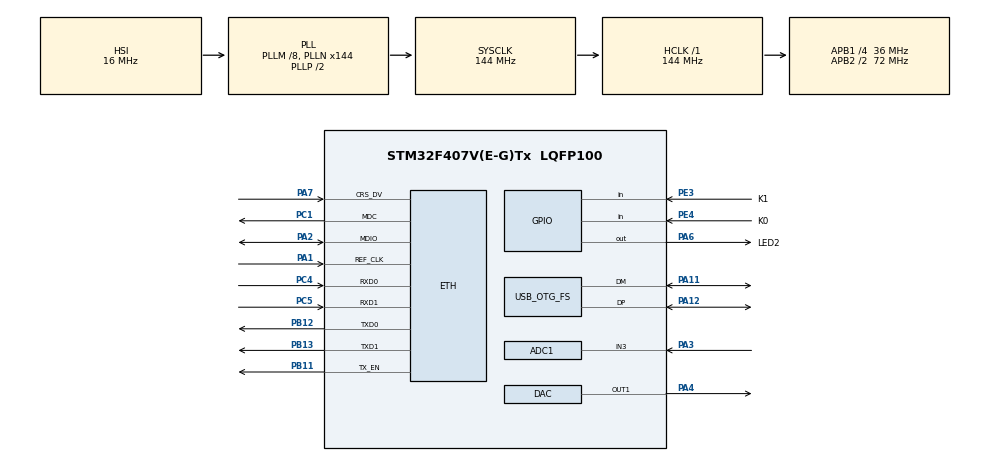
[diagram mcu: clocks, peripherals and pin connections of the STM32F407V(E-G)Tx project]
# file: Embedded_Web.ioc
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ADC1.Channel-8\#ChannelRegularConversion=ADC_CHANNEL_3
ADC1.ClockPrescaler=ADC_CLOCK_SYNC_PCLK_DIV6
ADC1.ContinuousConvMode=ENABLE
ADC1.DMAContinuousRequests=DISABLE
ADC1.DataAlign=ADC_DATAALIGN_RIGHT
ADC1.DiscontinuousConvMode=DISABLE
ADC1.EOCSelection=ADC_EOC_SEQ_CONV
ADC1.EnableAnalogWatchDog=false
ADC1.ExternalTrigConv=ADC_SOFTWARE_START
ADC1.ExternalTrigConvEdge=ADC_EXTERNALTRIGCONVEDGE_NONE
ADC1.InjNumberOfConversion=0
ADC1.NbrOfConversion=1
ADC1.NbrOfConversionFlag=1
ADC1.Rank-8\#ChannelRegularConversion=1
ADC1.Resolution=ADC_RESOLUTION_12B
ADC1.SamplingTime-8\#ChannelRegularConversion=ADC_SAMPLETIME_56CYCLES
ADC1.ScanConvMode=DISABLE
ADC1.master=1
ETH.MediaInterface=ETH_MEDIA_INTERFACE_RMII
FREERTOS.INCLUDE_vTaskDelayUntil=1
FREERTOS.Tasks01=defaultTask,0,128,StartDefaultTask,Default,NULL,Dynamic,NULL,NULL;Task2,-2,128,vTask2,Default,NULL,Dynamic,NULL,NULL;Task3,-2,128,vTask3,Default,NULL,Dynamic,NULL,NULL
FREERTOS.configMINIMAL_STACK_SIZE=128
FREERTOS.configUSE_COUNTING_SEMAPHORES=1
FREERTOS.configUSE_RECURSIVE_MUTEXES=1
LWIP.HTTPD_USE_CUSTOM_FSDATA=1
LWIP.LWIP_HTTPD=1
LWIP.LWIP_HTTPD_CGI=1
LWIP.LWIP_HTTPD_CGI_SSI=0
LWIP.LWIP_HTTPD_SSI=1
LWIP.LWIP_HTTPD_SSI_INCLUDE_TAG=0
LWIP.LWIP_HTTPD_SSI_RAW=0
LWIP.Version=v2.0.3_Cube
Mcu.Family=STM32F4
Mcu.Name=STM32F407V(E-G)Tx
Mcu.Package=LQFP100
NVIC.ETH_IRQn=true\:5\:0\:false\:false\:true\:true\:false
NVIC.OTG_FS_IRQn=true\:5\:0\:false\:false\:true\:true\:false
NVIC.PriorityGroup=NVIC_PRIORITYGROUP_4
NVIC.TIM1_UP_TIM10_IRQn=true\:0\:0\:false\:false\:true\:false\:false
NVIC.TIM6_DAC_IRQn=true\:5\:0\:false\:false\:true\:true\:true
NVIC.TimeBase=TIM1_UP_TIM10_IRQn
NVIC.TimeBaseIP=TIM1
PA0-WKUP.Signal=SYS_WKUP
PA1.Mode=RMII
PA1.Signal=ETH_REF_CLK
PA11.Mode=Device_Only
PA11.Signal=USB_OTG_FS_DM
PA12.Mode=Device_Only
PA12.Signal=USB_OTG_FS_DP
PA13.Mode=Trace_Asynchronous_SW
PA13.Signal=SYS_JTMS-SWDIO
PA14.Mode=Trace_Asynchronous_SW
PA14.Signal=SYS_JTCK-SWCLK
PA2.Mode=RMII
PA2.Signal=ETH_MDIO
PA3.Signal=ADCx_IN3
PA4.Signal=COMP_DAC1_group
PA6.GPIO_Label=LED2
PA6.PinState=GPIO_PIN_SET
PA6.Signal=GPIO_Output
PA7.Mode=RMII
PA7.Signal=ETH_CRS_DV
PB11.Mode=RMII
PB11.Signal=ETH_TX_EN
PB12.Mode=RMII
PB12.Signal=ETH_TXD0
PB13.Mode=RMII
PB13.Signal=ETH_TXD1
PB3.Mode=Trace_Asynchronous_SW
PB3.Signal=SYS_JTDO-SWO
PC1.Mode=RMII
PC1.Signal=ETH_MDC
PC14-OSC32_IN.Mode=LSE-External-Oscillator
PC14-OSC32_IN.Signal=RCC_OSC32_IN
PC15-OSC32_OUT.Mode=LSE-External-Oscillator
PC15-OSC32_OUT.Signal=RCC_OSC32_OUT
PC4.Mode=RMII
PC4.Signal=ETH_RXD0
PC5.Mode=RMII
PC5.Signal=ETH_RXD1
PE3.GPIO_Label=K1
PE3.Signal=GPIO_Input
PE4.GPIO_Label=K0
PE4.GPIO_PuPd=GPIO_PULLUP
PE4.Signal=GPIO_Input
PH0-OSC_IN.Mode=HSE-External-Oscillator
PH0-OSC_IN.Signal=RCC_OSC_IN
PH1-OSC_OUT.Mode=HSE-External-Oscillator
PH1-OSC_OUT.Signal=RCC_OSC_OUT
ProjectManager.HeapSize=0x4000
ProjectManager.StackSize=0x2000
ProjectManager.TargetToolchain=SW4STM32
RCC.48MHZClocksFreq_Value=48000000
RCC.AHBFreq_Value=144000000
RCC.APB1CLKDivider=RCC_HCLK_DIV4
RCC.APB1Freq_Value=36000000
RCC.APB1TimFreq_Value=72000000
RCC.APB2CLKDivider=RCC_HCLK_DIV2
RCC.APB2Freq_Value=72000000
RCC.APB2TimFreq_Value=144000000
RCC.CortexFreq_Value=144000000
RCC.HCLKFreq_Value=144000000
RCC.HSE_Timout=100
RCC.HSE_VALUE=8000000
RCC.HSICalibrationValue=17
RCC.HSI_VALUE=16000000
RCC.PLLM=8
RCC.PLLN=144
RCC.PLLQ=6
RCC.PLLSource=RCC_PLLSOURCE_HSI
RCC.PLLSourceVirtualString=RCC_PLLSOURCE_HSI
RCC.RCC_RTC_Clock_Source=RCC_RTCCLKSOURCE_LSE
RCC.RCC_RTC_Clock_SourceVirtual=RCC_RTCCLKSOURCE_LSE
RCC.SYSCLKFreq_VALUE=144000000
RCC.SYSCLKSource=RCC_SYSCLKSOURCE_PLLCLK
RCC.VCOOutputFreq_Value=288000000
RTC.Date=15
RTC.Hours=9
RTC.Month=RTC_MONTH_JUNE
RTC.Year=18
SH.ADCx_IN3.0=ADC1_IN3,IN3
SH.COMP_DAC1_group.0=DAC_OUT1,DAC_OUT1
USB_DEVICE.CLASS_NAME_FS=CDC
USB_DEVICE.VirtualMode-CDC_FS=Cdc
USB_DEVICE.VirtualModeFS=Cdc_FS
USB_OTG_FS.VirtualMode=Device_Only
VP_FREERTOS_VS_ENABLE.Mode=Enabled
VP_LWIP_VS_Enabled.Mode=Enabled
VP_RTC_VS_RTC_Activate.Mode=RTC_Enabled
VP_RTC_VS_RTC_Calendar.Mode=RTC_Calendar
VP_SYS_VS_tim1.Mode=TIM1
VP_USB_DEVICE_VS_USB_DEVICE_CDC_FS.Mode=CDC_FS
board=Embedded_Web

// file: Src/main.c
/**
  ******************************************************************************
  * @file           : main.c
  * @brief          : Main program body
  ******************************************************************************
  * This notice applies to any and all portions of this file
  * that are not between comment pairs USER CODE BEGIN and
  * USER CODE END. Other portions of this file, whether
  * inserted by the user or by software development tools
  * are owned by their respective copyright owners.
  *
  * Copyright (c) 2018 STMicroelectronics International N.V.
  * All rights reserved.
  *
  * Redistribution and use in source and binary forms, with or without
  * modification, are permitted, provided that the following conditions are met:
  *
  * 1. Redistribution of source code must retain the above copyright notice,
  *    this list of conditions and the following disclaimer.
  * 2. Redistributions in binary form must reproduce the above copyright notice,
  *    this list of conditions and the following disclaimer in the documentation
  *    and/or other materials provided with the distribution.
  * 3. Neither the name of STMicroelectronics nor the names of other
  *    contributors to this software may be used to endorse or promote products
  *    derived from this software without specific written permission.
  * 4. This software, including modifications and/or derivative works of this
  *    software, must execute solely and exclusively on microcontroller or
  *    microprocessor devices manufactured by or for STMicroelectronics.
  * 5. Redistribution and use of this software other than as permitted under
  *    this license is void and will automatically terminate your rights under
  *    this license.
  *
  * THIS SOFTWARE IS PROVIDED BY STMICROELECTRONICS AND CONTRIBUTORS "AS IS"
  * AND ANY EXPRESS, IMPLIED OR STATUTORY WARRANTIES, INCLUDING, BUT NOT
  * LIMITED TO, THE IMPLIED WARRANTIES OF MERCHANTABILITY, FITNESS FOR A
  * PARTICULAR PURPOSE AND NON-INFRINGEMENT OF THIRD PARTY INTELLECTUAL PROPERTY
  * RIGHTS ARE DISCLAIMED TO THE FULLEST EXTENT PERMITTED BY LAW. IN NO EVENT
  * SHALL STMICROELECTRONICS OR CONTRIBUTORS BE LIABLE FOR ANY DIRECT, INDIRECT,
  * INCIDENTAL, SPECIAL, EXEMPLARY, OR CONSEQUENTIAL DAMAGES (INCLUDING, BUT NOT
  * LIMITED TO, PROCUREMENT OF SUBSTITUTE GOODS OR SERVICES; LOSS OF USE, DATA,
  * OR PROFITS; OR BUSINESS INTERRUPTION) HOWEVER CAUSED AND ON ANY THEORY OF
  * LIABILITY, WHETHER IN CONTRACT, STRICT LIABILITY, OR TORT (INCLUDING
  * NEGLIGENCE OR OTHERWISE) ARISING IN ANY WAY OUT OF THE USE OF THIS SOFTWARE,
  * EVEN IF ADVISED OF THE POSSIBILITY OF SUCH DAMAGE.
  *
  ******************************************************************************
  */
#include "main.h"
#include "stm32f4xx_hal.h"
#include "cmsis_os.h"
#include "lwip.h"
#include "usb_device.h"

ADC_HandleTypeDef hadc1;

DAC_HandleTypeDef hdac;

RTC_HandleTypeDef hrtc;

osThreadId defaultTaskHandle;
osThreadId Task2Handle;
osThreadId Task3Handle;

/* USER CODE BEGIN PV */
/* Private variables ---------------------------------------------------------*/
// LED status variables
char LEDs[4];

/* USER CODE END PV */

void SystemClock_Config(void);
static void MX_GPIO_Init(void);
static void MX_DAC_Init(void);
static void MX_ADC1_Init(void);
static void MX_RTC_Init(void);
void StartDefaultTask(void const * argument);
void vTask2(void const * argument);
void vTask3(void const * argument);

/* USER CODE BEGIN PFP */
/* Private function prototypes -----------------------------------------------*/

/* USER CODE END PFP */

int main(void)
{

  /* MCU Configuration----------------------------------------------------------*/

  /* Reset of all peripherals, Initializes the Flash interface and the Systick. */
  HAL_Init();

  /* Configure the system clock */
  SystemClock_Config();

  /* Initialize all configured peripherals */
  MX_GPIO_Init();
  MX_DAC_Init();
  MX_ADC1_Init();
  MX_RTC_Init();

  /* Create the thread(s) */
  /* definition and creation of defaultTask */
  osThreadDef(defaultTask, StartDefaultTask, osPriorityNormal, 0, 128);
  defaultTaskHandle = osThreadCreate(osThread(defaultTask), NULL);

  /* definition and creation of Task2 */
  osThreadDef(Task2, vTask2, osPriorityLow, 0, 128);
  Task2Handle = osThreadCreate(osThread(Task2), NULL);

  /* definition and creation of Task3 */
  osThreadDef(Task3, vTask3, osPriorityLow, 0, 128);
  Task3Handle = osThreadCreate(osThread(Task3), NULL);

  /* Start scheduler */
  osKernelStart();

  /* We should never get here as control is now taken by the scheduler */

  /* Infinite loop */
  while (1)
  {

  }

}

void SystemClock_Config(void)
{

  RCC_OscInitTypeDef RCC_OscInitStruct;
  RCC_ClkInitTypeDef RCC_ClkInitStruct;
  RCC_PeriphCLKInitTypeDef PeriphClkInitStruct;

    /**Configure the main internal regulator output voltage
    */
  __HAL_RCC_PWR_CLK_ENABLE();

  __HAL_PWR_VOLTAGESCALING_CONFIG(PWR_REGULATOR_VOLTAGE_SCALE1);

    /**Initializes the CPU, AHB and APB busses clocks
    */
  RCC_OscInitStruct.OscillatorType = RCC_OSCILLATORTYPE_HSI|RCC_OSCILLATORTYPE_LSE;
  RCC_OscInitStruct.LSEState = RCC_LSE_ON;
  RCC_OscInitStruct.HSIState = RCC_HSI_ON;
  RCC_OscInitStruct.HSICalibrationValue = 17;
  RCC_OscInitStruct.PLL.PLLState = RCC_PLL_ON;
  RCC_OscInitStruct.PLL.PLLSource = RCC_PLLSOURCE_HSI;
  RCC_OscInitStruct.PLL.PLLM = 8;
  RCC_OscInitStruct.PLL.PLLN = 144;
  RCC_OscInitStruct.PLL.PLLP = RCC_PLLP_DIV2;
  RCC_OscInitStruct.PLL.PLLQ = 6;
  if (HAL_RCC_OscConfig(&RCC_OscInitStruct) != HAL_OK)
  {
    _Error_Handler(__FILE__, __LINE__);
  }

    /**Initializes the CPU, AHB and APB busses clocks
    */
  RCC_ClkInitStruct.ClockType = RCC_CLOCKTYPE_HCLK|RCC_CLOCKTYPE_SYSCLK
                              |RCC_CLOCKTYPE_PCLK1|RCC_CLOCKTYPE_PCLK2;
  RCC_ClkInitStruct.SYSCLKSource = RCC_SYSCLKSOURCE_PLLCLK;
  RCC_ClkInitStruct.AHBCLKDivider = RCC_SYSCLK_DIV1;
  RCC_ClkInitStruct.APB1CLKDivider = RCC_HCLK_DIV4;
  RCC_ClkInitStruct.APB2CLKDivider = RCC_HCLK_DIV2;

  if (HAL_RCC_ClockConfig(&RCC_ClkInitStruct, FLASH_LATENCY_4) != HAL_OK)
  {
    _Error_Handler(__FILE__, __LINE__);
  }

  PeriphClkInitStruct.PeriphClockSelection = RCC_PERIPHCLK_RTC;
  PeriphClkInitStruct.RTCClockSelection = RCC_RTCCLKSOURCE_LSE;
  if (HAL_RCCEx_PeriphCLKConfig(&PeriphClkInitStruct) != HAL_OK)
  {
    _Error_Handler(__FILE__, __LINE__);
  }

    /**Configure the Systick interrupt time
    */
  HAL_SYSTICK_Config(HAL_RCC_GetHCLKFreq()/1000);

    /**Configure the Systick
    */
  HAL_SYSTICK_CLKSourceConfig(SYSTICK_CLKSOURCE_HCLK);

  /* SysTick_IRQn interrupt configuration */
  HAL_NVIC_SetPriority(SysTick_IRQn, 15, 0);
}

/* ADC1 init function */
static void MX_ADC1_Init(void)
{

  ADC_ChannelConfTypeDef sConfig;

    /**Configure the global features of the ADC (Clock, Resolution, Data Alignment and number of conversion)
    */
  hadc1.Instance = ADC1;
  hadc1.Init.ClockPrescaler = ADC_CLOCK_SYNC_PCLK_DIV6;
  hadc1.Init.Resolution = ADC_RESOLUTION_12B;
  hadc1.Init.ScanConvMode = DISABLE;
  hadc1.Init.ContinuousConvMode = ENABLE;
  hadc1.Init.DiscontinuousConvMode = DISABLE;
  hadc1.Init.ExternalTrigConvEdge = ADC_EXTERNALTRIGCONVEDGE_NONE;
  hadc1.Init.ExternalTrigConv = ADC_SOFTWARE_START;
  hadc1.Init.DataAlign = ADC_DATAALIGN_RIGHT;
  hadc1.Init.NbrOfConversion = 1;
  hadc1.Init.DMAContinuousRequests = DISABLE;
  hadc1.Init.EOCSelection = ADC_EOC_SEQ_CONV;
  if (HAL_ADC_Init(&hadc1) != HAL_OK)
  {
    _Error_Handler(__FILE__, __LINE__);
  }

    /**Configure for the selected ADC regular channel its corresponding rank in the sequencer and its sample time.
    */
  sConfig.Channel = ADC_CHANNEL_3;
  sConfig.Rank = 1;
  sConfig.SamplingTime = ADC_SAMPLETIME_56CYCLES;
  if (HAL_ADC_ConfigChannel(&hadc1, &sConfig) != HAL_OK)
  {
    _Error_Handler(__FILE__, __LINE__);
  }

}

/* DAC init function */
static void MX_DAC_Init(void)
{

  DAC_ChannelConfTypeDef sConfig;

    /**DAC Initialization
    */
  hdac.Instance = DAC;
  if (HAL_DAC_Init(&hdac) != HAL_OK)
  {
    _Error_Handler(__FILE__, __LINE__);
  }

    /**DAC channel OUT1 config
    */
  sConfig.DAC_Trigger = DAC_TRIGGER_NONE;
  sConfig.DAC_OutputBuffer = DAC_OUTPUTBUFFER_ENABLE;
  if (HAL_DAC_ConfigChannel(&hdac, &sConfig, DAC_CHANNEL_1) != HAL_OK)
  {
    _Error_Handler(__FILE__, __LINE__);
  }

}

/* RTC init function */
static void MX_RTC_Init(void)
{

  RTC_TimeTypeDef sTime;
  RTC_DateTypeDef sDate;

    /**Initialize RTC Only
    */
  hrtc.Instance = RTC;
if(HAL_RTCEx_BKUPRead(&hrtc, RTC_BKP_DR0) != 0x32F2){
  hrtc.Init.HourFormat = RTC_HOURFORMAT_24;
  hrtc.Init.AsynchPrediv = 127;
  hrtc.Init.SynchPrediv = 255;
  hrtc.Init.OutPut = RTC_OUTPUT_DISABLE;
  hrtc.Init.OutPutPolarity = RTC_OUTPUT_POLARITY_HIGH;
  hrtc.Init.OutPutType = RTC_OUTPUT_TYPE_OPENDRAIN;
  if (HAL_RTC_Init(&hrtc) != HAL_OK)
  {
    _Error_Handler(__FILE__, __LINE__);
  }

    /**Initialize RTC and set the Time and Date
    */
  sTime.Hours = 0x9;
  sTime.Minutes = 0x0;
  sTime.Seconds = 0x0;
  sTime.DayLightSaving = RTC_DAYLIGHTSAVING_NONE;
  sTime.StoreOperation = RTC_STOREOPERATION_RESET;
  if (HAL_RTC_SetTime(&hrtc, &sTime, RTC_FORMAT_BCD) != HAL_OK)
  {
    _Error_Handler(__FILE__, __LINE__);
  }

  sDate.WeekDay = RTC_WEEKDAY_MONDAY;
  sDate.Month = RTC_MONTH_JUNE;
  sDate.Date = 0x15;
  sDate.Year = 0x18;

  if (HAL_RTC_SetDate(&hrtc, &sDate, RTC_FORMAT_BCD) != HAL_OK)
  {
    _Error_Handler(__FILE__, __LINE__);
  }

    HAL_RTCEx_BKUPWrite(&hrtc,RTC_BKP_DR0,0x32F2);
  }

}

/** Configure pins as
        * Analog
        * Input
        * Output
        * EVENT_OUT
        * EXTI
*/
static void MX_GPIO_Init(void)
{

  GPIO_InitTypeDef GPIO_InitStruct;

  /* GPIO Ports Clock Enable */
  __HAL_RCC_GPIOE_CLK_ENABLE();
  __HAL_RCC_GPIOC_CLK_ENABLE();
  __HAL_RCC_GPIOH_CLK_ENABLE();
  __HAL_RCC_GPIOA_CLK_ENABLE();
  __HAL_RCC_GPIOB_CLK_ENABLE();

  /*Configure GPIO pin Output Level */
  HAL_GPIO_WritePin(LED2_GPIO_Port, LED2_Pin, GPIO_PIN_SET);

  /*Configure GPIO pin : K1_Pin */
  GPIO_InitStruct.Pin = K1_Pin;
  GPIO_InitStruct.Mode = GPIO_MODE_INPUT;
  GPIO_InitStruct.Pull = GPIO_NOPULL;
  HAL_GPIO_Init(K1_GPIO_Port, &GPIO_InitStruct);

  /*Configure GPIO pin : K0_Pin */
  GPIO_InitStruct.Pin = K0_Pin;
  GPIO_InitStruct.Mode = GPIO_MODE_INPUT;
  GPIO_InitStruct.Pull = GPIO_PULLUP;
  HAL_GPIO_Init(K0_GPIO_Port, &GPIO_InitStruct);

  /*Configure GPIO pin : LED2_Pin */
  GPIO_InitStruct.Pin = LED2_Pin;
  GPIO_InitStruct.Mode = GPIO_MODE_OUTPUT_PP;
  GPIO_InitStruct.Pull = GPIO_NOPULL;
  GPIO_InitStruct.Speed = GPIO_SPEED_FREQ_LOW;
  HAL_GPIO_Init(LED2_GPIO_Port, &GPIO_InitStruct);

}

/* StartDefaultTask function */
void StartDefaultTask(void const * argument)
{
  /* init code for LWIP */
  MX_LWIP_Init();

  /* init code for USB_DEVICE */
  MX_USB_DEVICE_Init();

  /* USER CODE BEGIN 5 */
  // Initialize ssi and cgi hookups
  httpd_ssi_init();
  httpd_cgi_init();
  // Start http server with port 80
  httpd_init();

  /* Infinite loop */
  for(;;)
  {
    osDelay(1000);
  }
  /* USER CODE END 5 */
}

/* vTask2 function */
void vTask2(void const * argument)
{
  /* USER CODE BEGIN vTask2 */
  /* Infinite loop */
  for(;;)
  {
    osDelay(1000);
  }
  /* USER CODE END vTask2 */
}

/* vTask3 function */
void vTask3(void const * argument)
{
  /* USER CODE BEGIN vTask3 */
  /* Infinite loop */
  for(;;)
  {
    // For the LED test, uncomment the following lines
    //HAL_GPIO_WritePin(LED2_GPIO_Port, LED2_Pin, GPIO_PIN_SET);
    osDelay(500);
    //HAL_GPIO_WritePin(LED2_GPIO_Port, LED2_Pin, GPIO_PIN_RESET);
    osDelay(500);
  }
  /* USER CODE END vTask3 */
}

void HAL_TIM_PeriodElapsedCallback(TIM_HandleTypeDef *htim)
{
  if (htim->Instance == TIM1) {
    HAL_IncTick();
  }
}

void _Error_Handler(char *file, int line)
{
  while(1)
  {
  }
}

/************************ (C) COPYRIGHT STMicroelectronics *****END OF FILE****/
